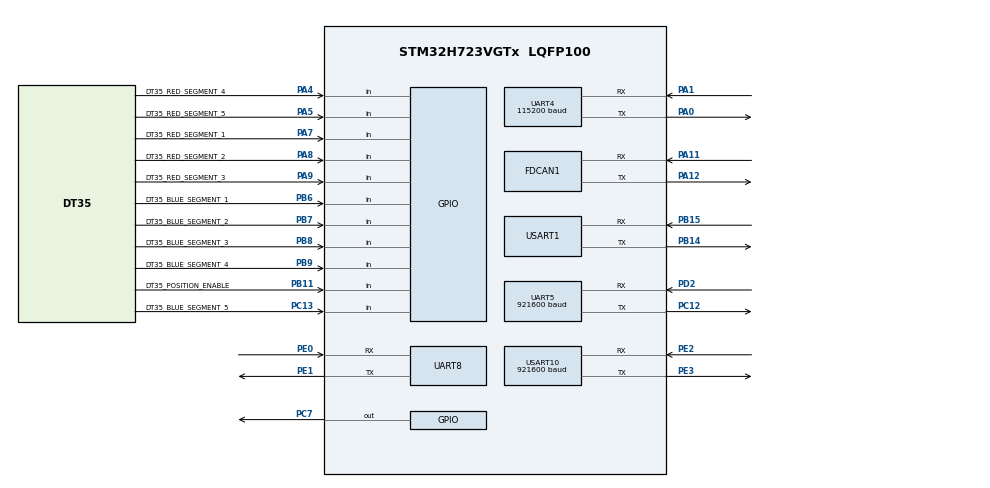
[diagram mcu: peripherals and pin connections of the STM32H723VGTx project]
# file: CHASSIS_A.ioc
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Dma.Request0=USART10_RX
Dma.Request1=USART10_TX
Dma.Request2=UART8_RX
Dma.Request3=UART8_TX
Dma.Request4=UART5_RX
Dma.Request5=UART4_RX
Dma.Request6=USART1_RX
Dma.Request7=USART1_TX
Dma.UART4_RX.5.Direction=DMA_PERIPH_TO_MEMORY
Dma.UART4_RX.5.EventEnable=DISABLE
Dma.UART4_RX.5.FIFOMode=DMA_FIFOMODE_DISABLE
Dma.UART4_RX.5.Instance=DMA1_Stream5
Dma.UART4_RX.5.MemDataAlignment=DMA_MDATAALIGN_BYTE
Dma.UART4_RX.5.MemInc=DMA_MINC_ENABLE
Dma.UART4_RX.5.Mode=DMA_NORMAL
Dma.UART4_RX.5.PeriphDataAlignment=DMA_PDATAALIGN_BYTE
Dma.UART4_RX.5.PeriphInc=DMA_PINC_DISABLE
Dma.UART4_RX.5.Polarity=HAL_DMAMUX_REQ_GEN_RISING
Dma.UART4_RX.5.Priority=DMA_PRIORITY_LOW
Dma.UART4_RX.5.RequestNumber=1
Dma.UART4_RX.5.SignalID=NONE
Dma.UART4_RX.5.SyncEnable=DISABLE
Dma.UART4_RX.5.SyncPolarity=HAL_DMAMUX_SYNC_NO_EVENT
Dma.UART4_RX.5.SyncRequestNumber=1
Dma.UART4_RX.5.SyncSignalID=NONE
Dma.UART5_RX.4.Direction=DMA_PERIPH_TO_MEMORY
Dma.UART5_RX.4.EventEnable=DISABLE
Dma.UART5_RX.4.FIFOMode=DMA_FIFOMODE_DISABLE
Dma.UART5_RX.4.Instance=DMA1_Stream4
Dma.UART5_RX.4.MemDataAlignment=DMA_MDATAALIGN_BYTE
Dma.UART5_RX.4.MemInc=DMA_MINC_ENABLE
Dma.UART5_RX.4.Mode=DMA_NORMAL
Dma.UART5_RX.4.PeriphDataAlignment=DMA_PDATAALIGN_BYTE
Dma.UART5_RX.4.PeriphInc=DMA_PINC_DISABLE
Dma.UART5_RX.4.Polarity=HAL_DMAMUX_REQ_GEN_RISING
Dma.UART5_RX.4.Priority=DMA_PRIORITY_LOW
Dma.UART5_RX.4.RequestNumber=1
Dma.UART5_RX.4.SignalID=NONE
Dma.UART5_RX.4.SyncEnable=DISABLE
Dma.UART5_RX.4.SyncPolarity=HAL_DMAMUX_SYNC_NO_EVENT
Dma.UART5_RX.4.SyncRequestNumber=1
Dma.UART5_RX.4.SyncSignalID=NONE
Dma.UART8_RX.2.Direction=DMA_PERIPH_TO_MEMORY
Dma.UART8_RX.2.EventEnable=DISABLE
Dma.UART8_RX.2.FIFOMode=DMA_FIFOMODE_DISABLE
Dma.UART8_RX.2.Instance=DMA1_Stream2
Dma.UART8_RX.2.MemDataAlignment=DMA_MDATAALIGN_BYTE
Dma.UART8_RX.2.MemInc=DMA_MINC_ENABLE
Dma.UART8_RX.2.Mode=DMA_CIRCULAR
Dma.UART8_RX.2.PeriphDataAlignment=DMA_PDATAALIGN_BYTE
Dma.UART8_RX.2.PeriphInc=DMA_PINC_DISABLE
Dma.UART8_RX.2.Polarity=HAL_DMAMUX_REQ_GEN_RISING
Dma.UART8_RX.2.Priority=DMA_PRIORITY_LOW
Dma.UART8_RX.2.RequestNumber=1
Dma.UART8_RX.2.SignalID=NONE
Dma.UART8_RX.2.SyncEnable=DISABLE
Dma.UART8_RX.2.SyncPolarity=HAL_DMAMUX_SYNC_NO_EVENT
Dma.UART8_RX.2.SyncRequestNumber=1
Dma.UART8_RX.2.SyncSignalID=NONE
Dma.UART8_TX.3.Direction=DMA_MEMORY_TO_PERIPH
Dma.UART8_TX.3.EventEnable=DISABLE
Dma.UART8_TX.3.FIFOMode=DMA_FIFOMODE_DISABLE
Dma.UART8_TX.3.Instance=DMA1_Stream3
Dma.UART8_TX.3.MemDataAlignment=DMA_MDATAALIGN_BYTE
Dma.UART8_TX.3.MemInc=DMA_MINC_ENABLE
Dma.UART8_TX.3.Mode=DMA_NORMAL
Dma.UART8_TX.3.PeriphDataAlignment=DMA_PDATAALIGN_BYTE
Dma.UART8_TX.3.PeriphInc=DMA_PINC_DISABLE
Dma.UART8_TX.3.Polarity=HAL_DMAMUX_REQ_GEN_RISING
Dma.UART8_TX.3.Priority=DMA_PRIORITY_LOW
Dma.UART8_TX.3.RequestNumber=1
Dma.UART8_TX.3.SignalID=NONE
Dma.UART8_TX.3.SyncEnable=DISABLE
Dma.UART8_TX.3.SyncPolarity=HAL_DMAMUX_SYNC_NO_EVENT
Dma.UART8_TX.3.SyncRequestNumber=1
Dma.UART8_TX.3.SyncSignalID=NONE
Dma.USART10_RX.0.Direction=DMA_PERIPH_TO_MEMORY
Dma.USART10_RX.0.EventEnable=DISABLE
Dma.USART10_RX.0.FIFOMode=DMA_FIFOMODE_DISABLE
Dma.USART10_RX.0.Instance=DMA1_Stream0
Dma.USART10_RX.0.MemDataAlignment=DMA_MDATAALIGN_BYTE
Dma.USART10_RX.0.MemInc=DMA_MINC_ENABLE
Dma.USART10_RX.0.Mode=DMA_CIRCULAR
Dma.USART10_RX.0.PeriphDataAlignment=DMA_PDATAALIGN_BYTE
Dma.USART10_RX.0.PeriphInc=DMA_PINC_DISABLE
Dma.USART10_RX.0.Polarity=HAL_DMAMUX_REQ_GEN_RISING
Dma.USART10_RX.0.Priority=DMA_PRIORITY_LOW
Dma.USART10_RX.0.RequestNumber=1
Dma.USART10_RX.0.SignalID=NONE
Dma.USART10_RX.0.SyncEnable=DISABLE
Dma.USART10_RX.0.SyncPolarity=HAL_DMAMUX_SYNC_NO_EVENT
Dma.USART10_RX.0.SyncRequestNumber=1
Dma.USART10_RX.0.SyncSignalID=NONE
Dma.USART10_TX.1.Direction=DMA_MEMORY_TO_PERIPH
Dma.USART10_TX.1.EventEnable=DISABLE
Dma.USART10_TX.1.FIFOMode=DMA_FIFOMODE_DISABLE
Dma.USART10_TX.1.Instance=DMA1_Stream1
Dma.USART10_TX.1.MemDataAlignment=DMA_MDATAALIGN_BYTE
Dma.USART10_TX.1.MemInc=DMA_MINC_ENABLE
Dma.USART10_TX.1.Mode=DMA_NORMAL
Dma.USART10_TX.1.PeriphDataAlignment=DMA_PDATAALIGN_BYTE
Dma.USART10_TX.1.PeriphInc=DMA_PINC_DISABLE
Dma.USART10_TX.1.Polarity=HAL_DMAMUX_REQ_GEN_RISING
Dma.USART10_TX.1.Priority=DMA_PRIORITY_LOW
Dma.USART10_TX.1.RequestNumber=1
Dma.USART10_TX.1.SignalID=NONE
Dma.USART10_TX.1.SyncEnable=DISABLE
Dma.USART10_TX.1.SyncPolarity=HAL_DMAMUX_SYNC_NO_EVENT
Dma.USART10_TX.1.SyncRequestNumber=1
Dma.USART10_TX.1.SyncSignalID=NONE
Dma.USART1_RX.6.Direction=DMA_PERIPH_TO_MEMORY
Dma.USART1_RX.6.EventEnable=DISABLE
Dma.USART1_RX.6.FIFOMode=DMA_FIFOMODE_DISABLE
Dma.USART1_RX.6.Instance=DMA1_Stream6
Dma.USART1_RX.6.MemDataAlignment=DMA_MDATAALIGN_BYTE
Dma.USART1_RX.6.MemInc=DMA_MINC_ENABLE
Dma.USART1_RX.6.Mode=DMA_CIRCULAR
Dma.USART1_RX.6.PeriphDataAlignment=DMA_PDATAALIGN_BYTE
Dma.USART1_RX.6.PeriphInc=DMA_PINC_DISABLE
Dma.USART1_RX.6.Polarity=HAL_DMAMUX_REQ_GEN_RISING
Dma.USART1_RX.6.Priority=DMA_PRIORITY_LOW
Dma.USART1_RX.6.RequestNumber=1
Dma.USART1_RX.6.SignalID=NONE
Dma.USART1_RX.6.SyncEnable=DISABLE
Dma.USART1_RX.6.SyncPolarity=HAL_DMAMUX_SYNC_NO_EVENT
Dma.USART1_RX.6.SyncRequestNumber=1
Dma.USART1_RX.6.SyncSignalID=NONE
Dma.USART1_TX.7.Direction=DMA_MEMORY_TO_PERIPH
Dma.USART1_TX.7.EventEnable=DISABLE
Dma.USART1_TX.7.FIFOMode=DMA_FIFOMODE_DISABLE
Dma.USART1_TX.7.Instance=DMA1_Stream7
Dma.USART1_TX.7.MemDataAlignment=DMA_MDATAALIGN_BYTE
Dma.USART1_TX.7.MemInc=DMA_MINC_ENABLE
Dma.USART1_TX.7.Mode=DMA_NORMAL
Dma.USART1_TX.7.PeriphDataAlignment=DMA_PDATAALIGN_BYTE
Dma.USART1_TX.7.PeriphInc=DMA_PINC_DISABLE
Dma.USART1_TX.7.Polarity=HAL_DMAMUX_REQ_GEN_RISING
Dma.USART1_TX.7.Priority=DMA_PRIORITY_LOW
Dma.USART1_TX.7.RequestNumber=1
Dma.USART1_TX.7.SignalID=NONE
Dma.USART1_TX.7.SyncEnable=DISABLE
Dma.USART1_TX.7.SyncPolarity=HAL_DMAMUX_SYNC_NO_EVENT
Dma.USART1_TX.7.SyncRequestNumber=1
Dma.USART1_TX.7.SyncSignalID=NONE
FDCAN1.AutoRetransmission=ENABLE
FDCAN1.CalculateBaudRateNominal=1000000
FDCAN1.CalculateTimeBitNominal=1000
FDCAN1.CalculateTimeQuantumNominal=62.5
FDCAN1.DataPrescaler=5
FDCAN1.DataSyncJumpWidth=2
FDCAN1.DataTimeSeg1=13
FDCAN1.DataTimeSeg2=2
FDCAN1.ExtFiltersNbr=1
FDCAN1.MessageRAMOffset=0
FDCAN1.NominalPrescaler=5
FDCAN1.NominalSyncJumpWidth=2
FDCAN1.NominalTimeSeg1=13
FDCAN1.NominalTimeSeg2=2
FDCAN1.RxFifo0ElmtsNbr=32
FDCAN1.StdFiltersNbr=1
FDCAN1.TxFifoQueueElmtsNbr=16
FREERTOS.Tasks01=defaultTask,32,1024,StartDefaultTask,Default,NULL,Dynamic,NULL,NULL
FREERTOS.configCHECK_FOR_STACK_OVERFLOW=2
FREERTOS.configENABLE_FPU=0
FREERTOS.configMAX_TASK_NAME_LEN=24
FREERTOS.configMINIMAL_STACK_SIZE=256
FREERTOS.configQUEUE_REGISTRY_SIZE=16
FREERTOS.configTOTAL_HEAP_SIZE=65536
FREERTOS.configUSE_MALLOC_FAILED_HOOK=1
Mcu.Family=STM32H7
Mcu.Name=STM32H723VGTx
Mcu.Package=LQFP100
NVIC.DMA1_Stream0_IRQn=true\:5\:0\:false\:false\:true\:true\:false\:true\:true
NVIC.DMA1_Stream1_IRQn=true\:5\:0\:false\:false\:true\:true\:false\:true\:true
NVIC.DMA1_Stream2_IRQn=true\:5\:0\:false\:false\:true\:true\:false\:true\:true
NVIC.DMA1_Stream3_IRQn=true\:5\:0\:false\:false\:true\:true\:false\:true\:true
NVIC.DMA1_Stream4_IRQn=true\:5\:0\:false\:false\:true\:true\:false\:true\:true
NVIC.DMA1_Stream5_IRQn=true\:5\:0\:false\:false\:true\:true\:false\:true\:true
NVIC.DMA1_Stream6_IRQn=true\:5\:0\:false\:false\:true\:true\:false\:true\:true
NVIC.DMA1_Stream7_IRQn=true\:5\:0\:false\:false\:true\:true\:false\:true\:true
NVIC.FDCAN1_IT0_IRQn=true\:5\:0\:false\:false\:true\:true\:true\:true\:true
NVIC.FDCAN1_IT1_IRQn=true\:5\:0\:false\:false\:true\:true\:true\:true\:true
NVIC.PriorityGroup=NVIC_PRIORITYGROUP_4
NVIC.TIM7_IRQn=true\:0\:0\:false\:false\:true\:false\:false\:true\:true
NVIC.TimeBase=TIM7_IRQn
NVIC.TimeBaseIP=TIM7
NVIC.UART4_IRQn=true\:5\:0\:false\:false\:true\:true\:true\:true\:true
NVIC.UART5_IRQn=true\:5\:0\:false\:false\:true\:true\:true\:true\:true
NVIC.UART8_IRQn=true\:5\:0\:false\:false\:true\:true\:true\:true\:true
NVIC.USART10_IRQn=true\:5\:0\:false\:false\:true\:true\:true\:true\:true
NVIC.USART1_IRQn=true\:5\:0\:false\:false\:true\:true\:true\:true\:true
PA0.Mode=Asynchronous
PA0.Signal=UART4_TX
PA1.Mode=Asynchronous
PA1.Signal=UART4_RX
PA11.Mode=FDCAN_Activate
PA11.Signal=FDCAN1_RX
PA12.Mode=FDCAN_Activate
PA12.Signal=FDCAN1_TX
PA13(JTMS/SWDIO).Mode=Serial_Wire
PA13(JTMS/SWDIO).Signal=DEBUG_JTMS-SWDIO
PA14(JTCK/SWCLK).Mode=Serial_Wire
PA14(JTCK/SWCLK).Signal=DEBUG_JTCK-SWCLK
PA4.GPIO_Label=DT35_RED_SEGMENT_4
PA4.GPIO_PuPd=GPIO_PULLDOWN
PA4.Signal=GPIO_Input
PA5.GPIO_Label=DT35_RED_SEGMENT_5
PA5.GPIO_PuPd=GPIO_PULLDOWN
PA5.Signal=GPIO_Input
PA7.GPIO_Label=DT35_RED_SEGMENT_1
PA7.GPIO_PuPd=GPIO_PULLDOWN
PA7.Signal=GPIO_Input
PA8.GPIO_Label=DT35_RED_SEGMENT_2
PA8.GPIO_PuPd=GPIO_PULLDOWN
PA8.Signal=GPIO_Input
PA9.GPIO_Label=DT35_RED_SEGMENT_3
PA9.GPIO_PuPd=GPIO_PULLDOWN
PA9.Signal=GPIO_Input
PB11.GPIO_Label=DT35_POSITION_ENABLE
PB11.GPIO_PuPd=GPIO_PULLDOWN
PB11.Signal=GPIO_Input
PB14.Mode=Asynchronous
PB14.Signal=USART1_TX
PB15.Mode=Asynchronous
PB15.Signal=USART1_RX
PB6.GPIO_Label=DT35_BLUE_SEGMENT_1
PB6.GPIO_PuPd=GPIO_PULLDOWN
PB6.Signal=GPIO_Input
PB7.GPIO_Label=DT35_BLUE_SEGMENT_2
PB7.GPIO_PuPd=GPIO_PULLDOWN
PB7.Signal=GPIO_Input
PB8.GPIO_Label=DT35_BLUE_SEGMENT_3
PB8.GPIO_PuPd=GPIO_PULLDOWN
PB8.Signal=GPIO_Input
PB9.GPIO_Label=DT35_BLUE_SEGMENT_4
PB9.GPIO_PuPd=GPIO_PULLDOWN
PB9.Signal=GPIO_Input
PC12.GPIO_Speed=GPIO_SPEED_FREQ_HIGH
PC12.Mode=Asynchronous
PC12.Signal=UART5_TX
PC13.GPIO_Label=DT35_BLUE_SEGMENT_5
PC13.GPIO_PuPd=GPIO_PULLDOWN
PC13.Signal=GPIO_Input
PC7.Signal=GPIO_Output
PD2.Mode=Asynchronous
PD2.Signal=UART5_RX
PE0.Mode=Asynchronous
PE0.Signal=UART8_RX
PE1.Mode=Asynchronous
PE1.Signal=UART8_TX
PE2.GPIO_Speed=GPIO_SPEED_FREQ_HIGH
PE2.Mode=Asynchronous
PE2.Signal=USART10_RX
PE3.GPIO_Speed=GPIO_SPEED_FREQ_HIGH
PE3.Mode=Asynchronous
PE3.Signal=USART10_TX
PH0-OSC_IN.Mode=HSE-External-Oscillator
PH0-OSC_IN.Signal=RCC_OSC_IN
PH1-OSC_OUT.Mode=HSE-External-Oscillator
PH1-OSC_OUT.Signal=RCC_OSC_OUT
ProjectManager.HeapSize=0x200
ProjectManager.StackSize=0x400
ProjectManager.TargetToolchain=MDK-ARM V5.32
RCC.ADCFreq_Value=200000000
RCC.APB1Freq_Value=137500000
RCC.APB2Freq_Value=137500000
RCC.APB3Freq_Value=137500000
RCC.APB4Freq_Value=137500000
RCC.CortexFreq_Value=550000000
RCC.D1PPRE=RCC_APB3_DIV2
RCC.D2PPRE1=RCC_APB1_DIV2
RCC.D2PPRE2=RCC_APB2_DIV2
RCC.D3PPRE=RCC_APB4_DIV2
RCC.DIVM1=2
RCC.DIVM2=5
RCC.DIVM3=5
RCC.DIVN1=44
RCC.DIVN2=80
RCC.DIVN3=40
RCC.DIVP1=1
RCC.DIVQ1=4
RCC.DIVQ2=5
RCC.FDCANCLockSelection=RCC_FDCANCLKSOURCE_PLL2
RCC.HCLKFreq_Value=275000000
RCC.HPRE=RCC_HCLK_DIV2
RCC.PLLFRACN=0
RCC.PLLSourceVirtual=RCC_PLLSOURCE_HSE
RCC.SYSCLKFreq_VALUE=550000000
RCC.SYSCLKSource=RCC_SYSCLKSOURCE_PLLCLK
RCC.USBCLockSelection=RCC_USBCLKSOURCE_PLL3
RCC.USBFreq_Value=100000000
UART4.BaudRate=115200
UART5.BaudRate=921600
USART1.VirtualMode-Asynchronous=VM_ASYNC
USART10.BaudRate=921600
USART10.VirtualMode=VM_ASYNC
VP_FREERTOS_VS_CMSIS_V2.Mode=CMSIS_V2
VP_MEMORYMAP_VS_MEMORYMAP.Mode=CurAppReg
VP_SYS_VS_tim7.Mode=TIM7
board=custom

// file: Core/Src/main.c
/* USER CODE BEGIN Header */
/**
  ******************************************************************************
  * @file           : main.c
  * @brief          : Main program body
  ******************************************************************************
  * @attention
  *
  * Copyright (c) 2026 STMicroelectronics.
  * All rights reserved.
  *
  * This software is licensed under terms that can be found in the LICENSE file
  * in the root directory of this software component.
  * If no LICENSE file comes with this software, it is provided AS-IS.
  *
  ******************************************************************************
  */
/* USER CODE END Header */
#include "main.h"
#include "FreeRTOS.h"
#include "cmsis_os2.h"
#include "dma.h"
#include "fdcan.h"
#include "usart.h"
#include "gpio.h"

/* USER CODE BEGIN Includes */
#include <stdio.h>

/* USER CODE END Includes */

/* USER CODE BEGIN PV */
static char tx_buf[32];

/* USER CODE END PV */

void SystemClock_Config(void);
void MX_FREERTOS_Init(void);

int main(void)
{

  /* MCU Configuration--------------------------------------------------------*/

  /* Reset of all peripherals, Initializes the Flash interface and the Systick. */
  HAL_Init();

  /* Configure the system clock */
  SystemClock_Config();

  /* Initialize all configured peripherals */
  MX_GPIO_Init();
  MX_DMA_Init();
  MX_UART4_Init();
  MX_UART8_Init();
  MX_USART10_UART_Init();
  MX_UART5_Init();
  MX_FDCAN1_Init();
  MX_USART1_UART_Init();

  /* Init scheduler */
  osKernelInitialize();  /* Call init function for freertos objects (in cmsis_os2.c) */
  MX_FREERTOS_Init();

  /* Start scheduler */
  osKernelStart();

  /* We should never get here as control is now taken by the scheduler */

  /* Infinite loop */
  while (1)
  {

  }
}

void SystemClock_Config(void)
{
  RCC_OscInitTypeDef RCC_OscInitStruct = {0};
  RCC_ClkInitTypeDef RCC_ClkInitStruct = {0};

  /** Supply configuration update enable
  */
  HAL_PWREx_ConfigSupply(PWR_LDO_SUPPLY);

  /** Configure the main internal regulator output voltage
  */
  __HAL_PWR_VOLTAGESCALING_CONFIG(PWR_REGULATOR_VOLTAGE_SCALE0);

  while(!__HAL_PWR_GET_FLAG(PWR_FLAG_VOSRDY)) {}

  /** Initializes the RCC Oscillators according to the specified parameters
  * in the RCC_OscInitTypeDef structure.
  */
  RCC_OscInitStruct.OscillatorType = RCC_OSCILLATORTYPE_HSE;
  RCC_OscInitStruct.HSEState = RCC_HSE_ON;
  RCC_OscInitStruct.PLL.PLLState = RCC_PLL_ON;
  RCC_OscInitStruct.PLL.PLLSource = RCC_PLLSOURCE_HSE;
  RCC_OscInitStruct.PLL.PLLM = 2;
  RCC_OscInitStruct.PLL.PLLN = 44;
  RCC_OscInitStruct.PLL.PLLP = 1;
  RCC_OscInitStruct.PLL.PLLQ = 4;
  RCC_OscInitStruct.PLL.PLLR = 2;
  RCC_OscInitStruct.PLL.PLLRGE = RCC_PLL1VCIRANGE_3;
  RCC_OscInitStruct.PLL.PLLVCOSEL = RCC_PLL1VCOWIDE;
  RCC_OscInitStruct.PLL.PLLFRACN = 0;
  if (HAL_RCC_OscConfig(&RCC_OscInitStruct) != HAL_OK)
  {
    Error_Handler();
  }

  /** Initializes the CPU, AHB and APB buses clocks
  */
  RCC_ClkInitStruct.ClockType = RCC_CLOCKTYPE_HCLK|RCC_CLOCKTYPE_SYSCLK
                              |RCC_CLOCKTYPE_PCLK1|RCC_CLOCKTYPE_PCLK2
                              |RCC_CLOCKTYPE_D3PCLK1|RCC_CLOCKTYPE_D1PCLK1;
  RCC_ClkInitStruct.SYSCLKSource = RCC_SYSCLKSOURCE_PLLCLK;
  RCC_ClkInitStruct.SYSCLKDivider = RCC_SYSCLK_DIV1;
  RCC_ClkInitStruct.AHBCLKDivider = RCC_HCLK_DIV2;
  RCC_ClkInitStruct.APB3CLKDivider = RCC_APB3_DIV2;
  RCC_ClkInitStruct.APB1CLKDivider = RCC_APB1_DIV2;
  RCC_ClkInitStruct.APB2CLKDivider = RCC_APB2_DIV2;
  RCC_ClkInitStruct.APB4CLKDivider = RCC_APB4_DIV2;

  if (HAL_RCC_ClockConfig(&RCC_ClkInitStruct, FLASH_LATENCY_3) != HAL_OK)
  {
    Error_Handler();
  }
}

void HAL_TIM_PeriodElapsedCallback(TIM_HandleTypeDef *htim)
{
  if (htim->Instance == TIM7)
  {
    HAL_IncTick();
  }
}

void Error_Handler(void)
{
  __disable_irq();
  while (1)
  {
  }
}

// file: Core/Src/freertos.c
/* USER CODE BEGIN Header */
/**
  ******************************************************************************
  * File Name          : freertos.c
  * Description        : Code for freertos applications
  ******************************************************************************
  * @attention
  *
  * Copyright (c) 2026 STMicroelectronics.
  * All rights reserved.
  *
  * This software is licensed under terms that can be found in the LICENSE file
  * in the root directory of this software component.
  * If no LICENSE file comes with this software, it is provided AS-IS.
  *
  ******************************************************************************
  */
/* USER CODE END Header */

#include "FreeRTOS.h"
#include "task.h"
#include "main.h"
#include "FreeRTOS.h"
#include "cmsis_os2.h"

/* USER CODE BEGIN Includes */
#include "app_rtos.h"

/* USER CODE END Includes */

/* Definitions for defaultTask */
osThreadId_t defaultTaskHandle;
const osThreadAttr_t defaultTask_attributes = {
  .name = "defaultTask",
  .stack_size = 1024 * 4,
  .priority = (osPriority_t) osPriorityAboveNormal,
};

void StartDefaultTask(void *argument);

void MX_FREERTOS_Init(void); /* (MISRA C 2004 rule 8.1) */

/* Hook prototypes */
void vApplicationStackOverflowHook(xTaskHandle xTask, char *pcTaskName);
void vApplicationMallocFailedHook(void);

/* USER CODE BEGIN 4 */
void vApplicationStackOverflowHook(xTaskHandle xTask, char *pcTaskName)
{
  (void)xTask;
  appRtosFaultFile = pcTaskName;
  AppRtos_Panic(APP_RTOS_FAULT_STACK_OVERFLOW);
}
/* USER CODE END 4 */

/* USER CODE BEGIN 5 */
void vApplicationMallocFailedHook(void)
{
  AppRtos_Panic(APP_RTOS_FAULT_MALLOC_FAILED);
}
/* USER CODE END 5 */

void MX_FREERTOS_Init(void) {
  /* USER CODE BEGIN Init */
  if (!AppRtos_Init())
  {
    AppRtos_Panic(APP_RTOS_FAULT_OBJECT_CREATE);
  }

  /* USER CODE END Init */

  /* Create the thread(s) */
  /* creation of defaultTask */
  defaultTaskHandle = osThreadNew(StartDefaultTask, NULL, &defaultTask_attributes);

}

void StartDefaultTask(void *argument)
{
  /* USER CODE BEGIN StartDefaultTask */
  (void)argument;
  AppRtos_Bootstrap();
  osThreadExit();
  /* USER CODE END StartDefaultTask */
}
